# MK26F18 register map
Vendor: Freescale Semiconductor, Inc.; Series: Kinetis_K; File version: 1.6
CPU: CM4 r0p1, little endian, no MPU, FPU, VTOR, 4 interrupt priority bits
Registers are 32-bit, read-write, reset 0x0 unless marked. A register's access mark holds for its fields unless they carry their own. Offsets are from the block's base; [hi:lo] are bit positions; {n}, {i} and the like mark numbered series.

## RNG — Random Number Generator Accelerator
Base 0x400A0000; register names take the prefix RNG_
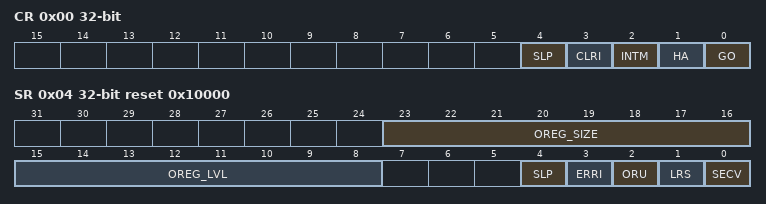
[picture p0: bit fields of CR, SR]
0x00 CR — RNGA Control Register
  [4] SLP — Sleep
    0=Normal mode; 1=Sleep (low-power) mode
  [3] CLRI wo — Clear Interrupt
    0=Do not clear the interrupt; 1=Clear the interrupt. When you write 1 to this field, RNGA then resets the error-interrupt indicator (SR[ERRI]). This bit always reads as 0.
  [2] INTM — Interrupt Mask
    0=Not masked; 1=Masked
  [1] HA — High Assurance
    0=Disabled; 1=Enabled
  [0] GO
    0=Disabled; 1=Enabled
0x04 SR ro reset 0x10000 — RNGA Status Register
  [23:16] OREG_SIZE — Output Register Size
    1=One word (this value is fixed)
  [15:8] OREG_LVL — Output Register Level
    0=No words (empty); 1=One word (valid)
  [4] SLP — Sleep
    0=Normal mode; 1=Sleep (low-power) mode
  [3] ERRI — Error Interrupt
    0=No underflow; 1=Underflow
  [2] ORU — Output Register Underflow
    0=No underflow; 1=Underflow
  [1] LRS — Last Read Status
    0=No underflow; 1=Underflow
  [0] SECV — Security Violation
    0=No security violation; 1=Security violation
0x08 ER wo — RNGA Entropy Register
  [31:0] EXT_ENT — External Entropy
0x0C OR ro — RNGA Output Register
  [31:0] RANDOUT — Random Output
    0=Invalid data (if you read this field when it is 0 and SR[OREG_LVL] is 0, RNGA then writes 1 to SR[ERRI], SR[ORU], and SR[LRS]; when the error interrupt is not masked (CR[INTM]=0), RNGA also asserts an error interrupt request to the interrupt controller)

## DAC0 — 12-Bit Digital-to-Analog Converter
Base 0x400CC000; register names take the prefix DAC0_
{0x0+2i} DAT{i}L (i=0..15) 8-bit — DAC Data Low Register
  [7:0] DATA0
{0x1+2i} DAT{i}H (i=0..15) 8-bit — DAC Data High Register
  [3:0] DATA1
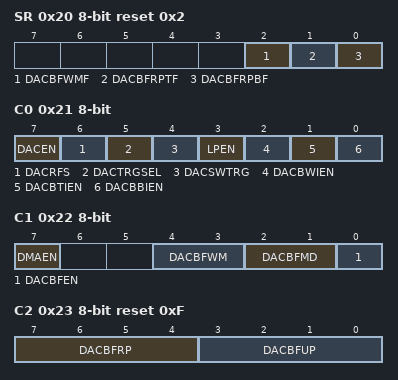
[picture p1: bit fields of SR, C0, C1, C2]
0x20 SR 8-bit reset 0x2 — DAC Status Register
  [2] DACBFWMF — DAC Buffer Watermark Flag
    0=The DAC buffer read pointer has not reached the watermark level; 1=The DAC buffer read pointer has reached the watermark level
  [1] DACBFRPTF — DAC Buffer Read Pointer Top Position Flag
    0=The DAC buffer read pointer is not zero; 1=The DAC buffer read pointer is zero
  [0] DACBFRPBF — DAC Buffer Read Pointer Bottom Position Flag
    0=The DAC buffer read pointer is not equal to C2[DACBFUP]; 1=The DAC buffer read pointer is equal to C2[DACBFUP]
0x21 C0 8-bit — DAC Control Register
  [7] DACEN — DAC Enable
    0=The DAC system is disabled; 1=The DAC system is enabled
  [6] DACRFS — DAC Reference Select
    0=The DAC selects DACREF_1 as the reference voltage; 1=The DAC selects DACREF_2 as the reference voltage
  [5] DACTRGSEL — DAC Trigger Select
    0=The DAC hardware trigger is selected; 1=The DAC software trigger is selected
  [4] DACSWTRG wo — DAC Software Trigger
    0=The DAC soft trigger is not valid; 1=The DAC soft trigger is valid
  [3] LPEN — DAC Low Power Control
    0=High-Power mode; 1=Low-Power mode
  [2] DACBWIEN — DAC Buffer Watermark Interrupt Enable
    0=The DAC buffer watermark interrupt is disabled; 1=The DAC buffer watermark interrupt is enabled
  [1] DACBTIEN — DAC Buffer Read Pointer Top Flag Interrupt Enable
    0=The DAC buffer read pointer top flag interrupt is disabled; 1=The DAC buffer read pointer top flag interrupt is enabled
  [0] DACBBIEN — DAC Buffer Read Pointer Bottom Flag Interrupt Enable
    0=The DAC buffer read pointer bottom flag interrupt is disabled; 1=The DAC buffer read pointer bottom flag interrupt is enabled
0x22 C1 8-bit — DAC Control Register 1
  [7] DMAEN — DMA Enable Select
    0=DMA is disabled; 1=DMA is enabled. When DMA is enabled, the DMA request will be generated by original interrupts. The interrupts will not be presented on this module at the same time.
  [4:3] DACBFWM — DAC Buffer Watermark Select
    0=1 word; 1=2 words; 2=3 words; 3=4 words
  [2:1] DACBFMD — DAC Buffer Work Mode Select
    0=Normal mode; 1=Swing mode; 2=One-Time Scan mode
  [0] DACBFEN — DAC Buffer Enable
    0=Buffer read pointer is disabled. The converted data is always the first word of the buffer.; 1=Buffer read pointer is enabled. The converted data is the word that the read pointer points to. It means converted data can be from any word of the buffer.
0x23 C2 8-bit reset 0xF — DAC Control Register 2
  [7:4] DACBFRP — DAC Buffer Read Pointer
  [3:0] DACBFUP — DAC Buffer Upper Limit

## DAC1 — 12-Bit Digital-to-Analog Converter
Base 0x400CD000; register names take the prefix DAC1_
Registers as DAC0.
